# N32G032 register map
Vendor: Nationstech Ltd.; File version: 1.0
Registers are 32-bit, read-write, reset 0x0 unless marked. A register's access mark holds for its fields unless they carry their own. Offsets are from the block's base; [hi:lo] are bit positions; {n}, {i} and the like mark numbered series.

## LPTIM — Low power timer control
Base 0x40000C00
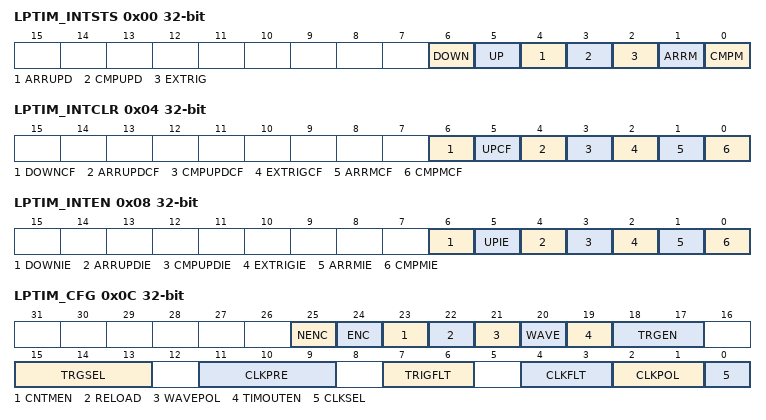
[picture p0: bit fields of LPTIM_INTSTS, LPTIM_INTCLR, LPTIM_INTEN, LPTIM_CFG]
0x00 LPTIM_INTSTS read
  [6] DOWN, [5] UP, [4] ARRUPD, [3] CMPUPD, [2] EXTRIG, [1] ARRM, [0] CMPM
0x04 LPTIM_INTCLR write
  [6] DOWNCF, [5] UPCF, [4] ARRUPDCF, [3] CMPUPDCF, [2] EXTRIGCF, [1] ARRMCF, [0] CMPMCF
0x08 LPTIM_INTEN
  [6] DOWNIE, [5] UPIE, [4] ARRUPDIE, [3] CMPUPDIE, [2] EXTRIGIE, [1] ARRMIE, [0] CMPMIE
0x0C LPTIM_CFG (reset mask 0x3FEEEEF)
  [25] NENC, [24] ENC, [23] CNTMEN, [22] RELOAD, [21] WAVEPOL, [20] WAVE, [19] TIMOUTEN, [18:17] TRGEN, [15:13] TRGSEL, [11:9] CLKPRE, [7:6] TRIGFLT, [4:3] CLKFLT, [2:1] CLKPOL, [0] CLKSEL
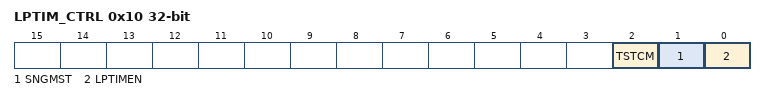
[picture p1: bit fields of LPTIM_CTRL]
0x10 LPTIM_CTRL
  [2] TSTCM, [1] SNGMST, [0] LPTIMEN
0x14 LPTIM_CMP
  [15:0] CMPVAL
0x18 LPTIM_ARR reset 0x1
  [15:0] ARRVAL
0x1C LPTIM_CNT reset 0x1
  [15:0] CNTVAL

## LPUART1 — Low-power universal asynchronous receiver transmitter
Base 0x40004800
Same registers: LPUART2 0x40004C00
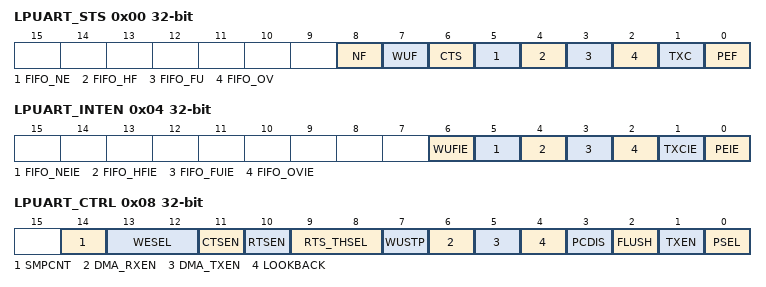
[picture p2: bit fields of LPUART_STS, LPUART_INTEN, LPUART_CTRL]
0x00 LPUART_STS
  [8] NF, [7] WUF, [6] CTS, [5] FIFO_NE, [4] FIFO_HF, [3] FIFO_FU, [2] FIFO_OV, [1] TXC, [0] PEF
0x04 LPUART_INTEN
  [6] WUFIE, [5] FIFO_NEIE, [4] FIFO_HFIE, [3] FIFO_FUIE, [2] FIFO_OVIE, [1] TXCIE, [0] PEIE
0x08 LPUART_CTRL
  [14] SMPCNT, [13:12] WESEL, [11] CTSEN, [10] RTSEN, [9:8] RTS_THSEL, [7] WUSTP, [6] DMA_RXEN, [5] DMA_TXEN, [4] LOOKBACK, [3] PCDIS, [2] FLUSH, [1] TXEN, [0] PSEL
0x0C LPUART_BRCFG1 reset 0x174
  [15:0] INTEGER
0x10 LPUART_DAT
  [7:0] DAT
0x14 LPUART_BRCFG2
  [7:0] DECIMAL
0x18 LPUART_WUDAT

## OPAMP — operational amplifier
Base 0x40002000
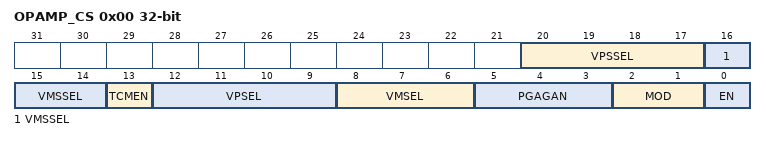
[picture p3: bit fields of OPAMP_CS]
0x00 OPAMP_CS
  [20:17] VPSSEL, [16:14] VMSSEL, [13] TCMEN, [12:9] VPSEL, [8:6] VMSEL, [5:3] PGAGAN, [2:1] MOD, [0] EN
0x04 OPAMP_LOCK
  [0] OPAMPLK

## PWR — Power control
Base 0x40007000
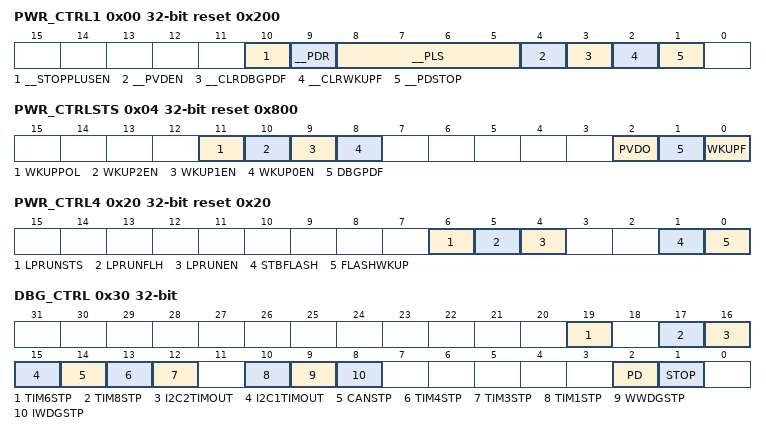
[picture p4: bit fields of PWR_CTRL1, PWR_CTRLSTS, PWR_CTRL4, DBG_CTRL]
0x00 PWR_CTRL1 reset 0x200 — PWR_CTRL
  [10] __STOPPLUSEN, [9] __PDR, [8:5] __PLS, [4] __PVDEN, [3] __CLRDBGPDF, [2] __CLRWKUPF, [1] __PDSTOP
0x04 PWR_CTRLSTS reset 0x800
  [11] WKUPPOL, [10] WKUP2EN, [9] WKUP1EN, [8] WKUP0EN, [2] PVDO, [1] DBGPDF, [0] WKUPF
0x08 PWR_CTRL2 reset 0x400
  [10] IWDGRSTEN
0x0C PWR_CTRL3 reset 0x37F
  [7] LSIEN
0x20 PWR_CTRL4 reset 0x20
  [6] LPRUNSTS, [5] LPRUNFLH, [4] LPRUNEN, [1] STBFLASH, [0] FLASHWKUP
0x24 PWR_CTRL5 reset 0x7 (reset mask 0xC0)
  [3:2] SLPMRSEL
0x28 PWR_CTRL6 (reset mask 0xC0)
  [3:2] STPMREN
0x30 DBG_CTRL
  [19] TIM6STP, [17] TIM8STP, [16] I2C2TIMOUT, [15] I2C1TIMOUT, [14] CANSTP, [13] TIM4STP, [12] TIM3STP, [10] TIM1STP, [9] WWDGSTP, [8] IWDGSTP, [2] PD, [1] STOP

## RCC — Reset and clock control
Base 0x40021000
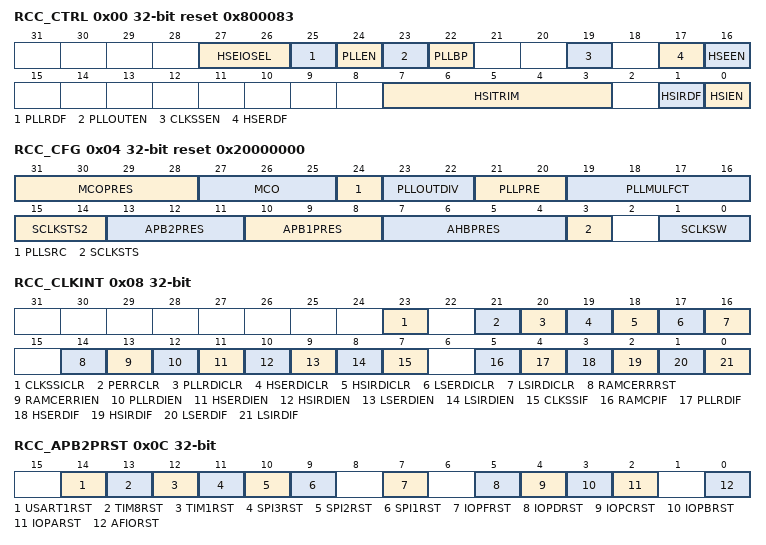
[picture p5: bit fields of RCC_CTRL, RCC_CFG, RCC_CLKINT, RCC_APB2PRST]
0x00 RCC_CTRL reset 0x800083
  [27:26] HSEIOSEL, [25] PLLRDF, [24] PLLEN, [23] PLLOUTEN, [22] PLLBP, [19] CLKSSEN, [17] HSERDF, [16] HSEEN, [7:3] HSITRIM, [1] HSIRDF, [0] HSIEN
0x04 RCC_CFG reset 0x20000000
  [31:28] MCOPRES, [27:25] MCO, [24] PLLSRC, [23:22] PLLOUTDIV, [21:20] PLLPRE, [19:16] PLLMULFCT, [15:14] SCLKSTS2, [13:11] APB2PRES, [10:8] APB1PRES, [7:4] AHBPRES, [3] SCLKSTS, [1:0] SCLKSW
0x08 RCC_CLKINT
  [23] CLKSSICLR, [21] PERRCLR, [20] PLLRDICLR, [19] HSERDICLR, [18] HSIRDICLR, [17] LSERDICLR, [16] LSIRDICLR, [14] RAMCERRRST, [13] RAMCERRIEN, [12] PLLRDIEN, [11] HSERDIEN, [10] HSIRDIEN, [9] LSERDIEN, [8] LSIRDIEN, [7] CLKSSIF, [5] RAMCPIF, [4] PLLRDIF, [3] HSERDIF, [2] HSIRDIF, [1] LSERDIF, [0] LSIRDIF
0x0C RCC_APB2PRST
  [14] USART1RST, [13] TIM8RST, [12] TIM1RST, [11] SPI3RST, [10] SPI2RST, [9] SPI1RST, [7] IOPFRST, [5] IOPDRST, [4] IOPCRST, [3] IOPBRST, [2] IOPARST, [0] AFIORST
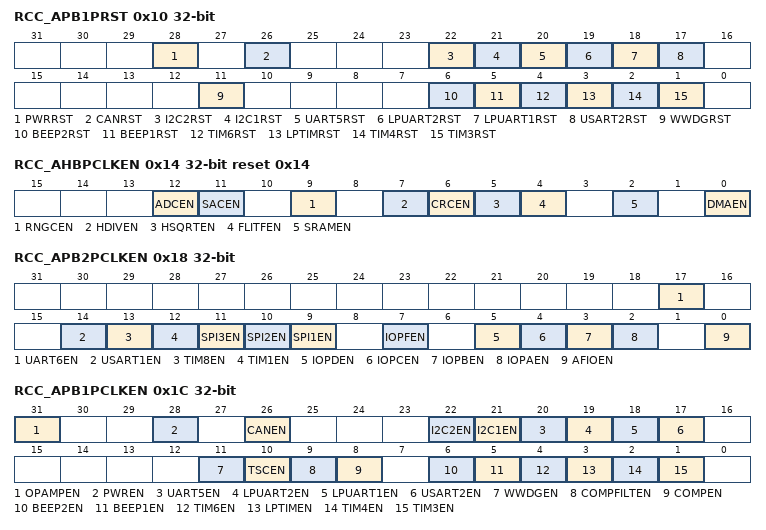
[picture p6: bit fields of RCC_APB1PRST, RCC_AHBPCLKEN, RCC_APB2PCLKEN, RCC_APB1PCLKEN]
0x10 RCC_APB1PRST
  [28] PWRRST, [26] CANRST, [22] I2C2RST, [21] I2C1RST, [20] UART5RST, [19] LPUART2RST, [18] LPUART1RST, [17] USART2RST, [11] WWDGRST, [6] BEEP2RST, [5] BEEP1RST, [4] TIM6RST, [3] LPTIMRST, [2] TIM4RST, [1] TIM3RST
0x14 RCC_AHBPCLKEN reset 0x14
  [12] ADCEN, [11] SACEN, [9] RNGCEN, [7] HDIVEN, [6] CRCEN, [5] HSQRTEN, [4] FLITFEN, [2] SRAMEN, [0] DMAEN
0x18 RCC_APB2PCLKEN
  [17] UART6EN, [14] USART1EN, [13] TIM8EN, [12] TIM1EN, [11] SPI3EN, [10] SPI2EN, [9] SPI1EN, [7] IOPFEN, [5] IOPDEN, [4] IOPCEN, [3] IOPBEN, [2] IOPAEN, [0] AFIOEN
0x1C RCC_APB1PCLKEN
  [31] OPAMPEN, [28] PWREN, [26] CANEN, [22] I2C2EN, [21] I2C1EN, [20] UART5EN, [19] LPUART2EN, [18] LPUART1EN, [17] USART2EN, [11] WWDGEN, [10] TSCEN, [9] COMPFILTEN, [8] COMPEN, [6] BEEP2EN, [5] BEEP1EN, [4] TIM6EN, [3] LPTIMEN, [2] TIM4EN, [1] TIM3EN
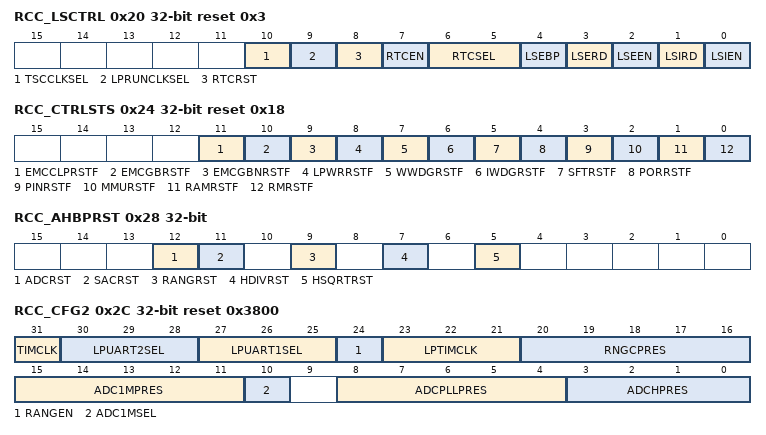
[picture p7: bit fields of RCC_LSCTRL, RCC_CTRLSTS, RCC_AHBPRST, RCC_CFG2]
0x20 RCC_LSCTRL reset 0x3
  [10] TSCCLKSEL, [9] LPRUNCLKSEL, [8] RTCRST, [7] RTCEN, [6:5] RTCSEL, [4] LSEBP, [3] LSERD, [2] LSEEN, [1] LSIRD, [0] LSIEN
0x24 RCC_CTRLSTS reset 0x18
  [11] EMCCLPRSTF, [10] EMCGBRSTF, [9] EMCGBNRSTF, [8] LPWRRSTF, [7] WWDGRSTF, [6] IWDGRSTF, [5] SFTRSTF, [4] PORRSTF, [3] PINRSTF, [2] MMURSTF, [1] RAMRSTF, [0] RMRSTF
0x28 RCC_AHBPRST
  [12] ADCRST, [11] SACRST, [9] RANGRST, [7] HDIVRST, [5] HSQRTRST
0x2C RCC_CFG2 reset 0x3800
  [31] TIMCLK, [30:28] LPUART2SEL, [27:25] LPUART1SEL, [24] RANGEN, [23:21] LPTIMCLK, [20:16] RNGCPRES, [15:11] ADC1MPRES, [10] ADC1MSEL, [8:4] ADCPLLPRES, [3:0] ADCHPRES
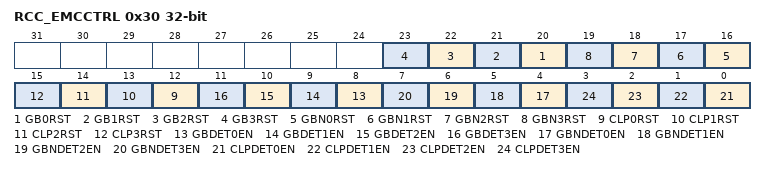
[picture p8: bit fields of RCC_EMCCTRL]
0x30 RCC_EMCCTRL
  [n+20] GB{n}RST (n=0..3), [n+16] GBN{n}RST (n=0..3), [n+12] CLP{n}RST (n=0..3), [n+8] GBDET{n}EN (n=0..3), [n+4] GBNDET{n}EN (n=0..3), [n] CLPDET{n}EN (n=0..3)
